# csr register map
Vendor: litex
Registers are 32-bit, read-write, reset 0x0 unless marked. A register's access mark holds for its fields unless they carry their own. Offsets are from the block's base; [hi:lo] are bit positions.

## ETHPHY
Base 0xF0001800
0x00 CRG_RESET
  [0] crg_reset
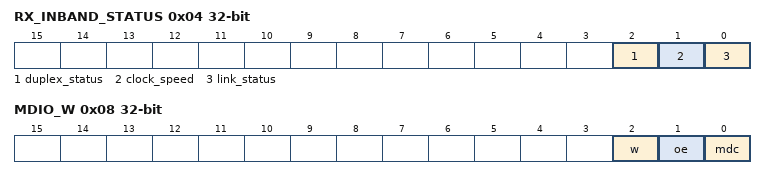
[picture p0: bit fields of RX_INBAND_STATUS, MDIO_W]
0x04 RX_INBAND_STATUS
  [2] duplex_status, [1] clock_speed, [0] link_status
0x08 MDIO_W
  [2] w, [1] oe, [0] mdc
0x0C MDIO_R
  [0] r

## I2C0
Base 0xF0002000
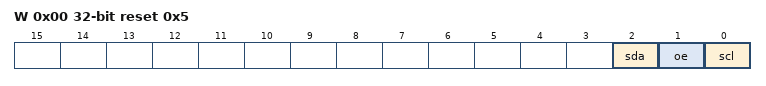
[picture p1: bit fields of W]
0x00 W reset 0x5
  [2] sda, [1] oe, [0] scl
0x04 R
  [0] sda

## IDENTIFIER_MEM
Base 0xF0002800
0x00 IDENTIFIER_MEM — 8 x 40-bit memory
  [7:0] identifier_mem

## SDRAM
Base 0xF0003000
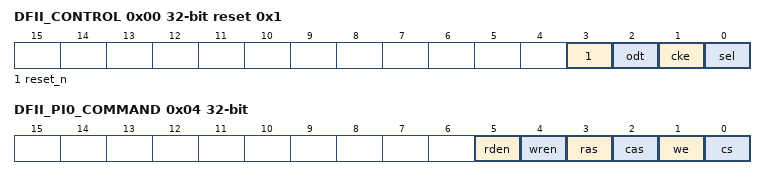
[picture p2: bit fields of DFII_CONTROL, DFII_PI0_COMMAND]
0x00 DFII_CONTROL reset 0x1 — Control DFI signals common to all phases
  [3] reset_n — DFI clock reset bus
  [2] odt — DFI on-die termination bus
  [1] cke — DFI clock enable bus
  [0] sel
0x04 DFII_PI0_COMMAND — Control DFI signals on a single phase
  [5] rden — DFI read data enable bus
  [4] wren — DFI write data enable bus
  [3] ras — DFI row address strobe bus
  [2] cas — DFI column address strobe bus
  [1] we — DFI write enable bus
  [0] cs — DFI chip select bus
0x08 DFII_PI0_COMMAND_ISSUE
  [0] dfii_pi0_command_issue
0x0C DFII_PI0_ADDRESS — DFI address bus
  [10:0] dfii_pi0_address
0x10 DFII_PI0_BADDRESS — DFI bank address bus
  [1:0] dfii_pi0_baddress
0x14 DFII_PI0_WRDATA — DFI write data bus
0x18 DFII_PI0_RDDATA — DFI read data bus

## SPIFLASH_CORE
Base 0xF0003800
0x00 MMAP_DUMMY_BITS
  [7:0] mmap_dummy_bits
0x04 MASTER_CS
  [0] master_cs
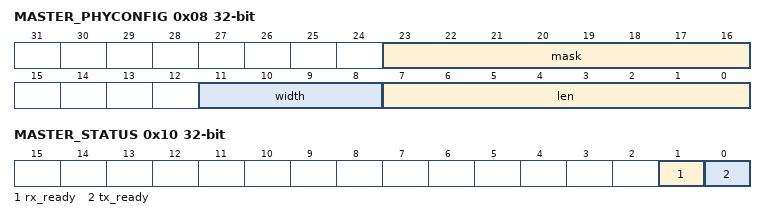
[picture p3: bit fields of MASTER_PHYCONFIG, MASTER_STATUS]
0x08 MASTER_PHYCONFIG — SPI PHY settings.
  [23:16] mask — SPI DQ output enable mask (set bits to ``1`` to enable output drivers on DQ lines).
  [11:8] width — SPI Xfer width (1/2/4/8).
  [7:0] len — SPI Xfer length (in bits).
0x0C MASTER_RXTX
0x10 MASTER_STATUS
  [1] rx_ready — RX FIFO is not empty.
  [0] tx_ready — TX FIFO is not full.

## SPIFLASH_PHY
Base 0xF0004000
0x00 CLK_DIVISOR reset 0x1
  [7:0] clk_divisor

## TIMER0
Base 0xF0004800
0x00 LOAD — Load value when Timer is (re-)enabled. In One-Shot mode, the value written to this register specifies the Timer's duration in clock cycles.
0x04 RELOAD — Reload value when Timer reaches ``0``. In Periodic mode, the value written to this register specify the Timer's period in clock cycles.
0x08 EN — Enable flag of the Timer. Set this flag to ``1`` to enable/start the Timer. Set to ``0`` to disable the Timer.
  [0] en
0x0C UPDATE_VALUE — Update trigger for the current countdown value. A write to this register latches the current countdown value to ``value`` register.
  [0] update_value
0x10 VALUE — Latched countdown value. This value is updated by writing to ``update_value``.
0x14 EV_STATUS — This register contains the current raw level of the zero event trigger. Writes to this register have no effect.
  [0] zero — Level of the ``zero`` event
0x18 EV_PENDING — When a zero event occurs, the corresponding bit will be set in this register. To clear the Event, set the corresponding bit in this register.
  [0] zero — `1` if a `zero` event occurred. This Event is triggered on a **falling** edge.
0x1C EV_ENABLE — This register enables the corresponding zero events. Write a ``0`` to this register to disable individual events.
  [0] zero — Write a ``1`` to enable the ``zero`` Event
0x20 UPTIME_LATCH — Write a ``1`` to latch current Uptime cycles to ``uptime_cycles`` register.
  [0] uptime_latch
0x24 UPTIME_CYCLES1 — Bits 32-63 of `TIMER0_UPTIME_CYCLES`. Latched Uptime since power-up (in ``sys_clk`` cycles).
  [31:0] uptime_cycles
0x28 UPTIME_CYCLES0 — Bits 0-31 of `TIMER0_UPTIME_CYCLES`.
  [31:0] uptime_cycles

## UART
Base 0xF0005000
0x00 RXTX
  [7:0] rxtx
0x04 TXFULL — TX FIFO Full.
  [0] txfull
0x08 RXEMPTY — RX FIFO Empty.
  [0] rxempty
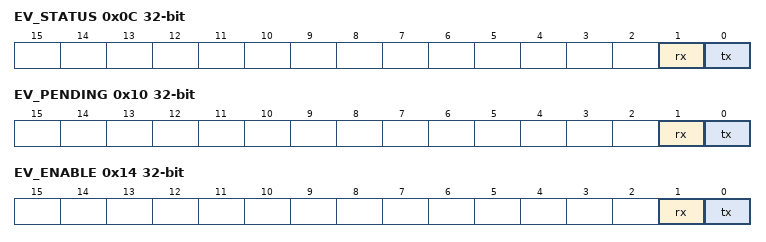
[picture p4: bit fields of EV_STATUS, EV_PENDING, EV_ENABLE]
0x0C EV_STATUS — This register contains the current raw level of the rx event trigger. Writes to this register have no effect.
  [1] rx — Level of the ``rx`` event
  [0] tx — Level of the ``tx`` event
0x10 EV_PENDING — When a rx event occurs, the corresponding bit will be set in this register. To clear the Event, set the corresponding bit in this register.
  [1] rx — `1` if a `rx` event occurred. This Event is triggered on a **falling** edge.
  [0] tx — `1` if a `tx` event occurred. This Event is triggered on a **falling** edge.
0x14 EV_ENABLE — This register enables the corresponding rx events. Write a ``0`` to this register to disable individual events.
  [1] rx — Write a ``1`` to enable the ``rx`` Event
  [0] tx — Write a ``1`` to enable the ``tx`` Event
0x18 TXEMPTY — TX FIFO Empty.
  [0] txempty
0x1C RXFULL — RX FIFO Full.
  [0] rxfull
